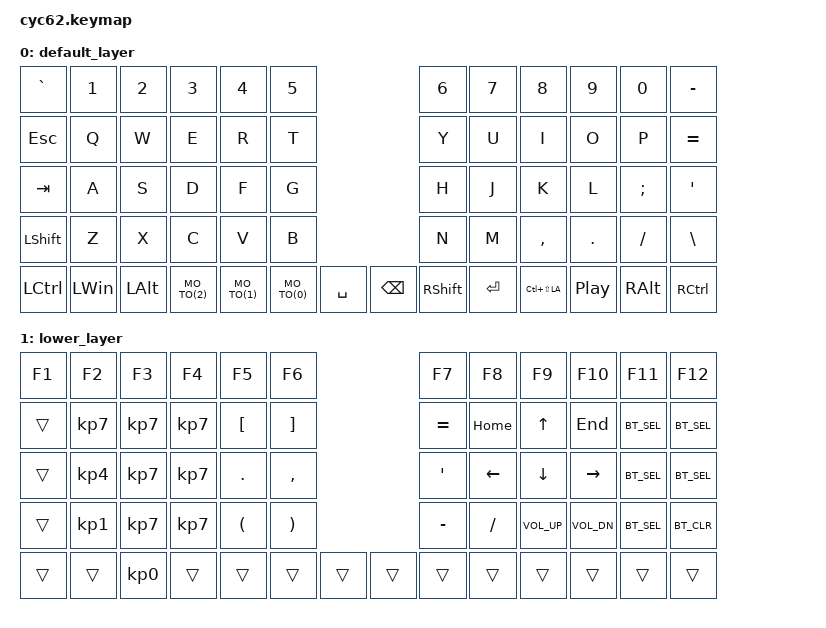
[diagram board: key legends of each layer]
#include <behaviors.dtsi>
#include <dt-bindings/zmk/keys.h>
#include <dt-bindings/zmk/bt.h>

#define MO_TO(layer) &mo_to layer layer

/ {
        keymap {
                compatible = "zmk,keymap";

                default_layer {
// ---------------------------------------------------------------------------------
// |  `~  |  1  |  2  |  3  |  4  |  5  |            |  6  |  7  |  8  |  9  |  0  |  _-  |
// |  ESC |  Q  |  W  |  E  |  R  |  T  |            |  Y  |  U  |  I  |  O  |  P  |  =+  |
// |  TAB |  A  |  S  |  D  |  F  |  G  |            |  H  |  J  |  K  |  L  |  ;  |  '"  |
// | SHFT |  Z  |  X  |  C  |  V  |  B  |            |  N  |  M  |  ,  |  .  |  /  |  \|  |
// | CTRL | WIN | ALT |  L2 |  L1 |  L0 | SPC || BSPC|RSHFT| ENTR| MEH | C_PP| ALT | CTRL |
                        bindings = <
   &kp GRAVE  &kp N1    &kp N2    &kp N3       &kp N4       &kp N5                              &kp N6     &kp N7    &kp N8         &kp N9    &kp N0    &kp MINUS
   &kp ESC    &kp Q     &kp W     &kp E        &kp R        &kp T                               &kp Y      &kp U     &kp I          &kp O     &kp P     &kp EQUAL
   &kp TAB    &kp A     &kp S     &kp D        &kp F        &kp G                               &kp H      &kp J     &kp K          &kp L     &kp SEMI  &kp APOS
   &kp LSHFT  &kp Z     &kp X     &kp C        &kp V        &kp B                               &kp N      &kp M     &kp COMMA      &kp DOT   &kp FSLH  &kp BSLH
   &kp LCTRL  &kp LWIN  &kp LALT  &kp MO_TO(2) &kp MO_TO(1) &kp MO_TO(0) &kp SPACE     &kp BSPC &kp RSHFT  &kp RET   &kp LC(LS(LA)) &kp C_PP  &kp RALT  &kp RCTRL
                        >;
                };
                lower_layer {
// ------------------------------------------------------------------------------------------------------------
// |   F1  |   F2  |   F3  |   F4  |   F5  |   F6  |                     |   F7  |   F8  |   F9  |  F10  |  F11  |  F12  |
// |       |   N7  |   N8  |   N9  |   [   |   ]   |                     |   +   |  HOME |   UP  |  END  |  BT1  |  BT2  |
// |       |   N4  |   N5  |   N6  |   .   |   ,   |                     |   "   |  LFT  |  DWN  |  RGT  |  BT3  |  BT4  |
// |       |   N1  |   N2  |   N3  |   (   |   )   |                     |   -   |   ?   |  VOL+ |  VOL- |  BT5  | BT CLR|
// |       |       |   N0  |       |       |       |       |     |       |       |       |       |       |       |       |
                        bindings = <
   &kp F1    &kp F2    &kp F3    &kp F4    &kp F5    &kp F6                           &kp F7    &kp F8    &kp F9       &kp F10      &kp F11      &kp F12
   &trans    &kp KP_N7 &kp KP_N7 &kp KP_N7 &kp LBKT  &kp RBKT                         &kp EQUAL &kp HOME  &kp UP       &kp END      &kp BT_SEL 0 &kp BT_SEL 1
   &trans    &kp KP_N4 &kp KP_N7 &kp KP_N7 &kp DOT   &kp COMMA                        &kp APOS  &kp LEFT  &kp DOWN     &kp RIGHT    &kp BT_SEL 2 &kp BT_SEL 3
   &trans    &kp KP_N1 &kp KP_N7 &kp KP_N7 &kp LPAR  &kp RPAR                         &kp MINUS &kp FSLH  &kp C_VOL_UP &kp C_VOL_DN &kp BT_SEL 4 &kp BT_CLR
   &trans    &trans    &kp KP_N0 &trans    &trans    &trans    &trans       &trans    &trans    &trans    &trans       &trans       &trans       &trans
                        >;
                };
        };
};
